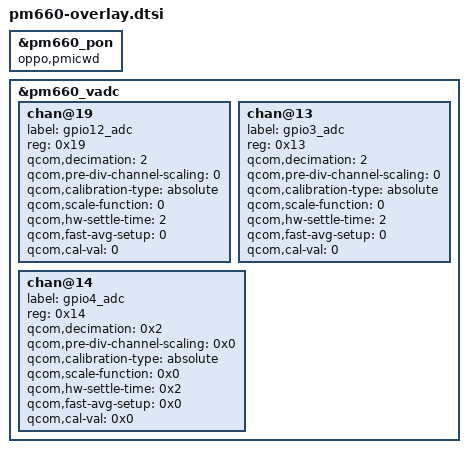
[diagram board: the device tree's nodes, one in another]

&pm660_pon {
    oppo,pmicwd;
};

&pm660_vadc {
	chan@19 {
		label = "gpio12_adc";
		reg = <0x19>; //channel for GPIO7
		qcom,decimation = <2>;
		qcom,pre-div-channel-scaling = <0>; //1:1 scaling
		qcom,calibration-type = "absolute";
		qcom,scale-function = <0>;
		qcom,hw-settle-time = <2>;
		qcom,fast-avg-setup = <0>;
		qcom,cal-val = <0>;
	};

	chan@13 {
		label = "gpio3_adc";
		reg = <0x13>; //channel for GPIO3
		qcom,decimation = <2>;
		qcom,pre-div-channel-scaling = <0>; //1:1 scaling
		qcom,calibration-type = "absolute";
		qcom,scale-function = <0>;
		qcom,hw-settle-time = <2>;
		qcom,fast-avg-setup = <0>;
		qcom,cal-val = <0>;
	};

	chan@14 {
		label = "gpio4_adc";
		reg = <0x14>;
		qcom,decimation = <0x2>;
		qcom,pre-div-channel-scaling = <0x0>;
		qcom,calibration-type = "absolute";
		qcom,scale-function = <0x0>;
		qcom,hw-settle-time = <0x2>;
		qcom,fast-avg-setup = <0x0>;
		qcom,cal-val = <0x0>;
	};
};
